AUTOSAR XML (schema 00046)
package /AUTOSAR/ComM_swc
  mode declaration group ComMMode: initial-mode=COMM_NO_COMMUNICATION
    mode COMM_NO_COMMUNICATION
    mode COMM_SILENT_COMMUNICATION
    mode COMM_FULL_COMMUNICATION
  data type mapping set ComMMode_DataTypeMappingSet: mode-request-type-map{implementation-data-type=ComM_ModeType, mode-group=ComMMode}  # Data Mapping for the Mode Declaration Group ComMMode.
package /AUTOSAR/ComM_swc/DataTypes
  6 x impl type:
    ComM_InhibitionStatusType: range raw 0..255, implementation-data-type=uint8
    ComM_ModeType: compu {0=COMM_NO_COMMUNICATION, 1=COMM_SILENT_COMMUNICATION, 2=COMM_FULL_COMMUNICATION}, range raw 0..3, implementation-data-type=uint8
    ComM_UserHandleType: range raw 0..65535, implementation-data-type=uint8
    NetworkHandleType: range raw 0..255, implementation-data-type=uint8, type-emitter=ComM
    ComM_UserHandleArrayType_ComMChannel_0: category=STRUCTURE, sw-calibration-access=READ-ONLY
      element numberOfRequesters: implementation-data-type=uint8
      element handleArray: implementation-data-type=ComM_UserHandleSubArrayType_ComMChannel_0
    ComM_UserHandleSubArrayType_ComMChannel_0: category=ARRAY, sw-calibration-access=READ-ONLY
      element ComM_UserHandleSubArrayType_ComMChannel_0Element: array-size=1, array-size-semantics=FIXED-SIZE, implementation-data-type=uint8
package /AUTOSAR/ComM_swc/Interfaces
  mode switch interface ComM_CurrentMode: is-service=true, service-kind=COM-MANAGER
    mode group currentMode: type=ComMMode
  4 x client server interface, all with is-service=true, service-kind=COM-MANAGER:
    ComM_UserRequest
      4 x operation:
        GetCurrentComMode: possible-error=[ComM_UserRequest/E_OK, ComM_UserRequest/E_NOT_OK]
          arg ComMode: type=ComM_ModeType, direction=OUT
        GetMaxComMode: possible-error=[ComM_UserRequest/E_OK, ComM_UserRequest/E_NOT_OK]
          arg ComMode: type=ComM_ModeType, direction=OUT
        GetRequestedComMode: possible-error=[ComM_UserRequest/E_OK, ComM_UserRequest/E_NOT_OK]
          arg ComMode: type=ComM_ModeType, direction=OUT
        RequestComMode: possible-error=[ComM_UserRequest/E_OK, ComM_UserRequest/E_NOT_OK, E_MODE_LIMITATION]
          arg ComMode: type=ComM_ModeType, direction=IN
      error E_OK: error-code=0
      error E_NOT_OK: error-code=1
      error E_MODE_LIMITATION: error-code=2
    ComM_ChannelLimitation
      operation GetInhibitionStatus: possible-error=[ComM_ChannelLimitation/E_OK, ComM_ChannelLimitation/E_NOT_OK]
        arg Status: type=ComM_InhibitionStatusType, direction=OUT
      operation LimitChannelToNoComMode: possible-error=[ComM_ChannelLimitation/E_OK, ComM_ChannelLimitation/E_NOT_OK]
        arg Status: type=boolean, direction=IN
      error E_OK: error-code=0
      error E_NOT_OK: error-code=1
    ComM_ECUModeLimitation
      4 x operation, all with possible-error=[ComM_ECUModeLimitation/E_OK, ComM_ECUModeLimitation/E_NOT_OK]:
        LimitECUToNoComMode
          arg Status: type=boolean, direction=IN
        ReadInhibitCounter
          arg CounterValue: type=uint16, direction=OUT
        ResetInhibitCounter
        SetECUGroupClassification
          arg Status: type=ComM_InhibitionStatusType, direction=IN
      error E_OK: error-code=0
      error E_NOT_OK: error-code=1
    ComM_ChannelWakeup
      operation GetInhibitionStatus: possible-error=[ComM_ChannelWakeup/E_OK, ComM_ChannelWakeup/E_NOT_OK]
        arg Status: type=ComM_InhibitionStatusType, direction=OUT
      operation PreventWakeUp: possible-error=[ComM_ChannelWakeup/E_OK, ComM_ChannelWakeup/E_NOT_OK]
        arg Status: type=boolean, direction=IN
      error E_OK: error-code=0
      error E_NOT_OK: error-code=1
package /AUTOSAR/ComM_swc/ComponentTypes
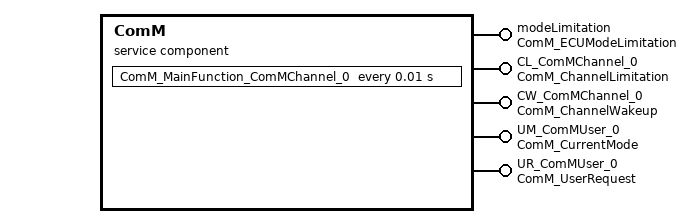
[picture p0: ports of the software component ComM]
  service sw component type ComM: category=SERVICE_COMPONENT
    5 x provide port:
      modeLimitation: provided-interface=ComM_ECUModeLimitation
      CL_ComMChannel_0: provided-interface=ComM_ChannelLimitation
      CW_ComMChannel_0: provided-interface=ComM_ChannelWakeup
      UM_ComMUser_0: provided-interface=ComM_CurrentMode
      UR_ComMUser_0: provided-interface=ComM_UserRequest
    behavior ComMInternalBehavior: data-type-mapping=ComMMode_DataTypeMappingSet, handle-termination-and-restart=NO-SUPPORT, included-data-type-set=data-type=[ComM_ModeType, ComM_InhibitionStatusType, ComM_UserHandleType, NetworkHandleType]
      timing event Timer_ComM_MainFunction_ComMChannel_0: start-on-event=ComM_MainFunction_ComMChannel_0, period=0.01
      12 x operation invoked event:
        OpEventLimitECUToNoComMode_LimitECUToNoComMode_modeLimitation: start-on-event=LimitECUToNoComMode, operation=modeLimitation.LimitECUToNoComMode
        OpEventReadInhibitCounter_ReadInhibitCounter_modeLimitation: start-on-event=ReadInhibitCounter, operation=modeLimitation.ReadInhibitCounter
        OpEventResetInhibitCounter_ResetInhibitCounter_modeLimitation: start-on-event=ResetInhibitCounter, operation=modeLimitation.ResetInhibitCounter
        OpEventSetECUGroupClassification_SetECUGroupClassification_modeLimitation: start-on-event=SetECUGroupClassification, operation=modeLimitation.SetECUGroupClassification
        OpEventGetInhibitionStatus_GetInhibitionStatus_CL_ComMChannel_0: start-on-event=GetInhibitionStatus, operation=CL_ComMChannel_0.GetInhibitionStatus
        OpEventLimitChannelToNoComMode_LimitChannelToNoComMode_CL_ComMChannel_0: start-on-event=LimitChannelToNoComMode, operation=CL_ComMChannel_0.LimitChannelToNoComMode
        OpEventGetInhibitionStatus_GetInhibitionStatus_CW_ComMChannel_0: start-on-event=GetInhibitionStatus, operation=CW_ComMChannel_0.GetInhibitionStatus
        OpEventPreventWakeUp_PreventWakeUp_CW_ComMChannel_0: start-on-event=PreventWakeUp, operation=CW_ComMChannel_0.PreventWakeUp
        OpEventGetCurrentComMode_GetCurrentComMode_UR_ComMUser_0: start-on-event=GetCurrentComMode, operation=UR_ComMUser_0.GetCurrentComMode
        OpEventGetMaxComMode_GetMaxComMode_UR_ComMUser_0: start-on-event=GetMaxComMode, operation=UR_ComMUser_0.GetMaxComMode
        OpEventGetRequestedComMode_GetRequestedComMode_UR_ComMUser_0: start-on-event=GetRequestedComMode, operation=UR_ComMUser_0.GetRequestedComMode
        OpEventRequestComMode_RequestComMode_UR_ComMUser_0: start-on-event=RequestComMode, operation=UR_ComMUser_0.RequestComMode
      port-api-options:
        enable-take-address=true, indirect-api=false, port=modeLimitation
        {enable-take-address=true, indirect-api=false, port-defined-argument-value{value=0, value-type=NetworkHandleType}, port=CL_ComMChannel_0}
        {enable-take-address=true, indirect-api=false, port-defined-argument-value{value=0, value-type=NetworkHandleType}, port=CW_ComMChannel_0}
        enable-take-address=true, indirect-api=false, port=UM_ComMUser_0
        {enable-take-address=true, indirect-api=false, port-defined-argument-value{value=0, value-type=ComM_UserHandleType}, port=UR_ComMUser_0}
      12 x runnable, all with can-be-invoked-concurrently=true:
        ComM_MainFunction_ComMChannel_0
          mode switch point SWITCH_UM_ComMUser_0_ComMMode: mode-group=UM_ComMUser_0.currentMode
        GetCurrentComMode: symbol=ComM_GetCurrentComMode
        GetMaxComMode: symbol=ComM_GetMaxComMode
        GetRequestedComMode: symbol=ComM_GetRequestedComMode
        RequestComMode: symbol=ComM_RequestComMode
        GetInhibitionStatus: symbol=ComM_GetInhibitionStatus
        LimitChannelToNoComMode: symbol=ComM_LimitChannelToNoComMode
        LimitECUToNoComMode: symbol=ComM_LimitECUToNoComMode
        ReadInhibitCounter: symbol=ComM_ReadInhibitCounter
        ResetInhibitCounter: symbol=ComM_ResetInhibitCounter
        SetECUGroupClassification: symbol=ComM_SetECUGroupClassification
        PreventWakeUp: symbol=ComM_PreventWakeUp
  swc implementation ComMImplementation: programming-language=C, behavior=ComMInternalBehavior
